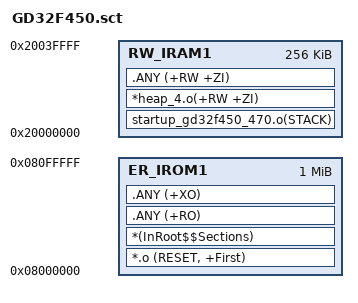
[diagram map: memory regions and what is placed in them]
; *************************************************************
; *** Scatter-Loading Description File generated by uVision ***
; *************************************************************

LR_IROM1 0x08000000 0x00100000  {    ; load region size_region
  ER_IROM1 0x08000000 0x00100000  {  ; load address = execution address
   *.o (RESET, +First)
   *(InRoot$$Sections)
   .ANY (+RO)
   .ANY (+XO)
  }
RW_IRAM1 0x20000000 0x00040000 {  ; 256KB内部RAM
  startup_gd32f450_470.o(STACK)   ; 栈
  *heap_4.o(+RW +ZI)              ; FreeRTOS堆
  .ANY (+RW +ZI)                  ; 其他变量（避免包含显存）
}


}

